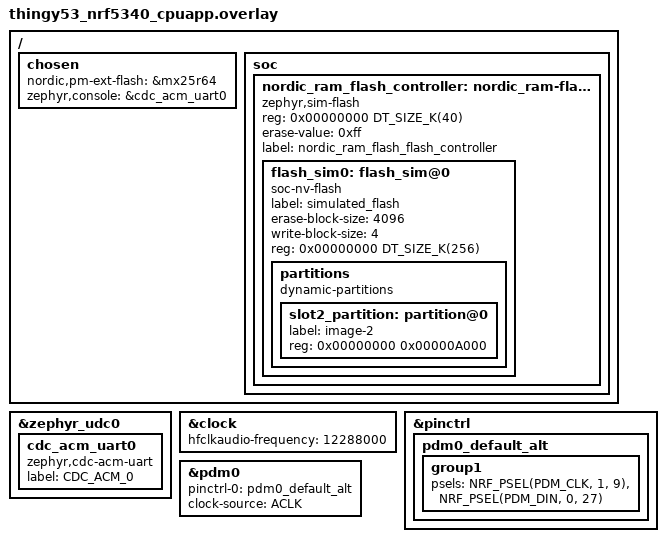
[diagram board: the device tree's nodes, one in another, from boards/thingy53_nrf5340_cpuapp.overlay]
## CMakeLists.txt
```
#
# Copyright (c) 2018 Nordic Semiconductor ASA
#
# SPDX-License-Identifier: LicenseRef-Nordic-5-Clause
#

cmake_minimum_required(VERSION 3.13.1)

find_package(Zephyr REQUIRED HINTS $ENV{ZEPHYR_BASE})
project(ble_to_cloud_from_scratch)

# NORDIC SDK APP START
target_sources(app PRIVATE src/main.c)
# NORDIC SDK APP END

# Include source directory
target_include_directories(app PRIVATE src)

add_subdirectory(src/events)
add_subdirectory(src/modules)
# add_subdirectory(src/led)

add_subdirectory_ifdef(CONFIG_THINGY53 src/battery)
```

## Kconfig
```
#
# Copyright (c) 2021 Nordic Semiconductor ASA
#
# SPDX-License-Identifier: LicenseRef-Nordic-5-Clause
#

menu "HIVE_HUB"

# 

config THINGY53
	bool "Flag for if you're using a Thingy or not."
	default n

config THINGY53_LOGGING
	bool "Flag for if you want Thingy:53 to log."
	default n

config HIGH_RES_SAMPLING_THINGY
	bool "Enable for high sample rate on Thingy52"
	default n
	
config BEE_COUNTER_NAME
	string "Name of your Bee Counter Device"
	default "ItsyBitsy"

config BEE_COUNTER_ENABLE
	bool "Enable if you want the device to connect to the Bee Counter"
	default y

#Add Broodminder address, if we figure out how to add an address

config BROODMINDER_WEIGHT_ENABLE
	bool "Enable if you want the device to scan for the Broodminder Weight"
	default y

config BROODMINDER_WEIGHT_NAME
	string "Name of your broodminder weight, in the format of xx:yy:zz"
	default "57:01:FD"

config WOODPECKER_ENABLE
	bool "Enable if you want the device to run Edge Impulse woodpecker detector"
	default y
	select AUDIO
	select AUDIO_DMIC

config WOODPECKER_SAMPLE_RATE
	int "Time between Edge Impulse woodpecker detector data get sent to nRF91"
	default 30

config THINGY_ENABLE
	bool "Enable if you want the device to connect to a Thingy:52"
	default y

config THINGY_CONNECTIONS
	int "Number of Thingy:52 in the hive"
	default 0 if !THINGY_ENABLE
	default 1

config THINGY_NAME
	string "Name of your thingy"
	default "Thingy"

config THINGY_SAMPLE_RATE 
	int "Thingy:52 sample rate in seconds"
	default 60

# default horizon: 12 = 1hour for default res sampling
# high res horizon: 60 = 1 hour for high res sampling 
# Aiming for default = 24 for default res sampling and 120 for high res
config THINGY_DATA_BUFFER_SIZE
	int "Size of Thingy data buffer- This decides the time horizon"
	default 120 if HIGH_RES_SAMPLING_THINGY
	default 12

#For high res: 20 (every 20th minute with 1 min sample time)
#For default res: 4 (every 20th minute with 5 min sample time)
config THINGY_SAMPLE_TO_SEND
	int "Send data every nth minute"
	default 20 if HIGH_RES_SAMPLING_THINGY
	default 4
	# default 1	

config BLE_TO_CLOUD_APP_VERSION
	string "Bluetooth to cloud application firmware version"
	default "0.0.0-development"

config BLE_TO_CLOUD_APP_VERSION_MAX_LEN
	int "Maximum length of application firmware version"
	default 150

config WATCHDOG_ENABLE
	bool "Enable if you want the watchdog timer to be active"
	default n

endmenu

menu "Zephyr Kernel"
source "Kconfig.zephyr"
endmenu

module = APPLICATION_MODULE
module-str = Application module
source "subsys/logging/Kconfig.template.log_config"
```

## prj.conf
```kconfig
#
# Copyright (c) 2020 Nordic Semiconductor ASA
#
# SPDX-License-Identifier: LicenseRef-Nordic-5-Clause
#
# Enable Event manager
CONFIG_APP_EVENT_MANAGER=y
CONFIG_LINKER_ORPHAN_SECTION_PLACE=y

# Enable DK LED and Buttons library
CONFIG_DK_LIBRARY=y

# Bluetooth section #
CONFIG_BT=y
CONFIG_BT_SMP=y
CONFIG_BT_CENTRAL=y
# Enable scanning for peripherals
CONFIG_BT_SCAN=y
CONFIG_BT_SCAN_FILTER_ENABLE=y
# Should be equal or higher than amount of peripheral modules enabled
CONFIG_BT_SCAN_NAME_CNT=2
CONFIG_BT_SCAN_ADDRESS_CNT=1

CONFIG_BT_GATT_DM=y
CONFIG_HEAP_MEM_POOL_SIZE=8192
CONFIG_BT_MAX_CONN=10
CONFIG_BT_MAX_PAIRED=10

# Enable the NUS service
CONFIG_BT_NUS=y
CONFIG_BT_NUS_CLIENT=y

# Enable bonding
CONFIG_BT_SETTINGS=y
CONFIG_FLASH=y
CONFIG_FLASH_PAGE_LAYOUT=y
CONFIG_FLASH_MAP=y
CONFIG_NVS=y
CONFIG_SETTINGS=y

### Thingy section ###
# Enable the BLE stack with GATT Client configuration
CONFIG_BT_GATT_CLIENT=y
# Number of characteristics that can be discovered/subscribed to in one bt_gatt_dm_cb 
CONFIG_BT_L2CAP_TX_BUF_COUNT=20

### Broodminder section ###

CONFIG_CBPRINTF_FP_SUPPORT=y

# This example requires more workqueue stack
CONFIG_SYSTEM_WORKQUEUE_STACK_SIZE=4096

### Peripheral section ###
CONFIG_BT_PERIPHERAL=y
CONFIG_BT_DEVICE_NAME="Hive4" # Different than Hive1 to avoid acccidental connection to wrong device.
CONFIG_BT_DEVICE_APPEARANCE=833

# Enable logging
CONFIG_LOG=y
CONFIG_LOG_DEFAULT_LEVEL=4
CONFIG_ASSERT=y

CONFIG_USE_SEGGER_RTT=n
CONFIG_RTT_CONSOLE=n
CONFIG_UART_CONSOLE=y

CONFIG_LOG_BACKEND_RTT=n
CONFIG_LOG_BACKEND_RTT_BUFFER_SIZE=4096

### Module configurations ###
CONFIG_BROODMINDER_WEIGHT_ENABLE=n

CONFIG_BEE_COUNTER_ENABLE=n

# CONFIG_THINGY_ENABLE=n
# CONFIG_HIGH_RES_SAMPLING_THINGY=y
CONFIG_THINGY_SAMPLE_RATE=30
CONFIG_THINGY_NAME="Hive4Thingy"
CONFIG_THINGY_DATA_BUFFER_SIZE=20
CONFIG_THINGY_SAMPLE_TO_SEND=2

CONFIG_WOODPECKER_ENABLE=n
CONFIG_WOODPECKER_SAMPLE_RATE=3

### Dependencies of the woodpecker module, comment out if CONFIG_WOODPECKER=n ###
# Enable Edge Impulse dependencies
# CONFIG_CPLUSPLUS=y
# CONFIG_STD_CPP11=y
# CONFIG_LIB_CPLUSPLUS=y
# CONFIG_NEWLIB_LIBC=y
# CONFIG_NEWLIB_LIBC_FLOAT_PRINTF=y
# CONFIG_FP16=n

# # Enable Edge Impulse
# CONFIG_EDGE_IMPULSE=y
# CONFIG_EDGE_IMPULSE_URI="woodpeckerdetector-v31.zip"
# CONFIG_EI_WRAPPER=y
# CONFIG_EI_WRAPPER_DATA_BUF_SIZE=18000
# CONFIG_EI_WRAPPER_PROFILING=y

## Watchdog ##
CONFIG_WATCHDOG_ENABLE=y
CONFIG_WATCHDOG=y
CONFIG_WDT_LOG_LEVEL_DBG=y
CONFIG_WDT_DISABLE_AT_BOOT=y
CONFIG_TASK_WDT=y
CONFIG_TASK_WDT_MIN_TIMEOUT=500

## NVS ##
CONFIG_FLASH=y
CONFIG_FLASH_PAGE_LAYOUT=y
CONFIG_NVS=y
CONFIG_LOG=y
CONFIG_NVS_LOG_LEVEL_DBG=y
CONFIG_REBOOT=y
CONFIG_MPU_ALLOW_FLASH_WRITE=y
```

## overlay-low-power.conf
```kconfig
#
# Copyright (c) 2021 Nordic Semiconductor ASA
#
# SPDX-License-Identifier: LicenseRef-Nordic-5-Clause
#

# This file contains configurations to achieve the lowest power consumption by
# disabling logging over RTT.
CONFIG_DK_LIBRARY=n

CONFIG_LOG=n
CONFIG_SERIAL=n

CONFIG_USE_SEGGER_RTT=n
CONFIG_RTT_CONSOLE=n
CONFIG_UART_CONSOLE=n
CONFIG_PRINTK=n
CONFIG_LOG_BACKEND_RTT=n
```

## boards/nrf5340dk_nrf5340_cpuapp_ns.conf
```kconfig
# CONFIG_TFM_PROFILE_TYPE_MINIMAL=y
```

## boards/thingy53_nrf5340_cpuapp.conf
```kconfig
CONFIG_THINGY53=y
CONFIG_ADC=y

# CONFIG_BROODMINDER_WEIGHT_NAME="47:05:9B"
```

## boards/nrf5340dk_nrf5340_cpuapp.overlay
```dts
&clock {
    hfclkaudio-frequency = <12288000>;
};
&pinctrl {
    pdm0_default_alt: pdm0_default_alt {
        group1 {
            psels = <NRF_PSEL(PDM_CLK, 1, 5)>,
                <NRF_PSEL(PDM_DIN, 1, 6)>;
        };
    };
};
dmic_dev: &pdm0 {
    status = "okay";
    pinctrl-0 = <&pdm0_default_alt>;
    pinctrl-names = "default";
    clock-source = "ACLK";
};
```

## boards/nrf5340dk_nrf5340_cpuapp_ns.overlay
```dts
// /* Disable uart0 to conserve power */
// &uart0 {
// 	status = "disabled";
// };
/* Disable uart2 in nonsecure since it is used by the TFM secure app. */
&uart2 {
		status = "disabled";
};

/* Disable uart1 in nonsecure since it is used by the TFM secure app, must be disabled when using low power mode. */
&uart1 {
	status = "disabled";
};
```

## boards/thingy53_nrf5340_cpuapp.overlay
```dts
// // /* Disable uart0 to conserve power */
// &uart0 {
// 	status = "disabled";
// };
// /* Disable uart2 in nonsecure since it is used by the TFM secure app. */
// &uart2 {
// 		status = "disabled";
// };

// /* Disable uart1 in nonsecure since it is used by the TFM secure app, must be disabled when using low power mode. */
// &uart1 {
// 	status = "disabled";
// };

/ {
	chosen {
		nordic,pm-ext-flash = &mx25r64;
	};
};



/ {
	soc {
		/* Add a flash controller which has the compatible
		 * 'zephyr,sim-flash'. This will ensure that the flash
		 * simulator can use it. None of the other properties in this
		 * node is used for anything.
		 */
		nordic_ram_flash_controller: nordic_ram-flash-controller@0 {
			compatible = "zephyr,sim-flash";
			reg = <0x00000000 DT_SIZE_K(40)>;
			#address-cells = <1>;
			#size-cells = <1>;
			erase-value = <0xff>;
			label = "nordic_ram_flash_flash_controller";

			/* This node label must match that used in the flash
			 * simulator.
			 */
			flash_sim0: flash_sim@0 {
				status = "okay";
				compatible = "soc-nv-flash";
				label = "simulated_flash";
				erase-block-size = <4096>;
				write-block-size = <4>;
				reg = <0x00000000 DT_SIZE_K(256)>;

				partitions {
					compatible = "dynamic-partitions";
					#address-cells = <1>;
					#size-cells = <1>;

					/* This partition must be defined for
					 * MCUboot to find the partition ID
					 * of the primary slot for image 1,
					 * which is stored in this partition.
					 */
					slot2_partition: partition@0 {
						label = "image-2";
						reg = <0x00000000 0x00000A000>;
					};
				};
			};
		};
	};

	chosen {
		zephyr,console = &cdc_acm_uart0;
	};
};

&zephyr_udc0 {
	cdc_acm_uart0: cdc_acm_uart0 {
		compatible = "zephyr,cdc-acm-uart";
		label = "CDC_ACM_0";
	};
};


&clock {
    hfclkaudio-frequency = <12288000>;
};
&pinctrl {
    pdm0_default_alt: pdm0_default_alt {
        group1 {
            psels = <NRF_PSEL(PDM_CLK, 1, 9)>,
                <NRF_PSEL(PDM_DIN, 0, 27)>;
        };
    };
};
dmic_dev: &pdm0 {
    status = "okay";
    pinctrl-0 = <&pdm0_default_alt>;
    pinctrl-names = "default";
    clock-source = "ACLK";
};
```

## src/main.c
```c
/*
 * Copyright (c) 2018 Nordic Semiconductor ASA
 *
 * SPDX-License-Identifier: LicenseRef-Nordic-5-Clause
 */
#define MODULE app_module

#include <zephyr.h>
#include <stdio.h>
#include <drivers/uart.h>
#include <string.h>
#include <logging/log.h>
#include <dk_buttons_and_leds.h>

#include <settings/settings.h>

#include <app_event_manager.h>
#include <drivers/gpio.h>
#include <sys/reboot.h>

LOG_MODULE_REGISTER(MODULE, CONFIG_APPLICATION_MODULE_LOG_LEVEL);

bool led_on;

void main(void)
{	

	LOG_INF("In main() main.c");

#if defined(CONFIG_THINGY53)
	/* Disable unnecessary peripherals to save power. */ 
	const struct device *gpio0_dev;
	gpio0_dev = device_get_binding("GPIO_0");
	int err = gpio_pin_configure(gpio0_dev, 31, GPIO_OUTPUT_LOW); //SENS POWER CONTROL
	err = gpio_pin_configure(gpio0_dev, 8, GPIO_OUTPUT_LOW); //PMIC MODE
	err = gpio_pin_configure(gpio0_dev, 18, GPIO_OUTPUT_HIGH); //Set External flash CS' High to turn it off
	err = gpio_pin_configure(gpio0_dev, 22, GPIO_OUTPUT_HIGH); //Set ADXL365 CS' High to turn it off

	/* Toggle the red led to signal that the program has started */
	err = gpio_pin_configure(gpio0_dev, 15, GPIO_OUTPUT_LOW); //3V3 ENABLE (LOW means on, need for LED's) 
	const struct device *gpio1_dev;
	gpio1_dev = device_get_binding("GPIO_1");
	err = gpio_pin_configure(gpio1_dev, 8, GPIO_OUTPUT_HIGH); //Red led	
	
	k_sleep(K_MSEC(500));
	
	err = gpio_pin_configure(gpio1_dev, 8, GPIO_OUTPUT_LOW);  //Red led	
	err = gpio_pin_configure(gpio0_dev, 15, GPIO_OUTPUT_HIGH); //3V3 ENABLE (HIGH means off)
	#endif
	if(app_event_manager_init()){
		LOG_INF("Well this sucks");
	}
	else{
		LOG_INF("All good");
		uint32_t resetreas = NRF_RESET->RESETREAS;
		LOG_INF("%08x", resetreas);
	}
}
```
